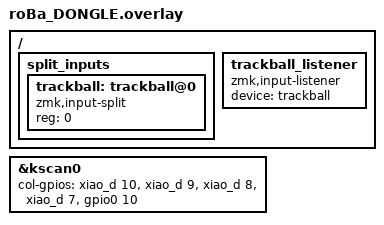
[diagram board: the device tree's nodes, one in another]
#include "roBa.dtsi"

&kscan0 {
        col-gpios
            = <&xiao_d 10 GPIO_ACTIVE_HIGH>
            , <&xiao_d 9 GPIO_ACTIVE_HIGH> 
            , <&xiao_d 8 GPIO_ACTIVE_HIGH> 
            , <&xiao_d 7 GPIO_ACTIVE_HIGH> 
            , <&gpio0 10 GPIO_ACTIVE_HIGH>
            ;
};


/ {
    split_inputs {
        #address-cells = <1>;
        #size-cells = <0>;

        trackball: trackball@0 {
            compatible = "zmk,input-split";
            reg = <0>;
        };
    };

    trackball_listener: trackball_listener {
        compatible = "zmk,input-listener";
        status = "okay";
        device = <&trackball>;
    };
};
